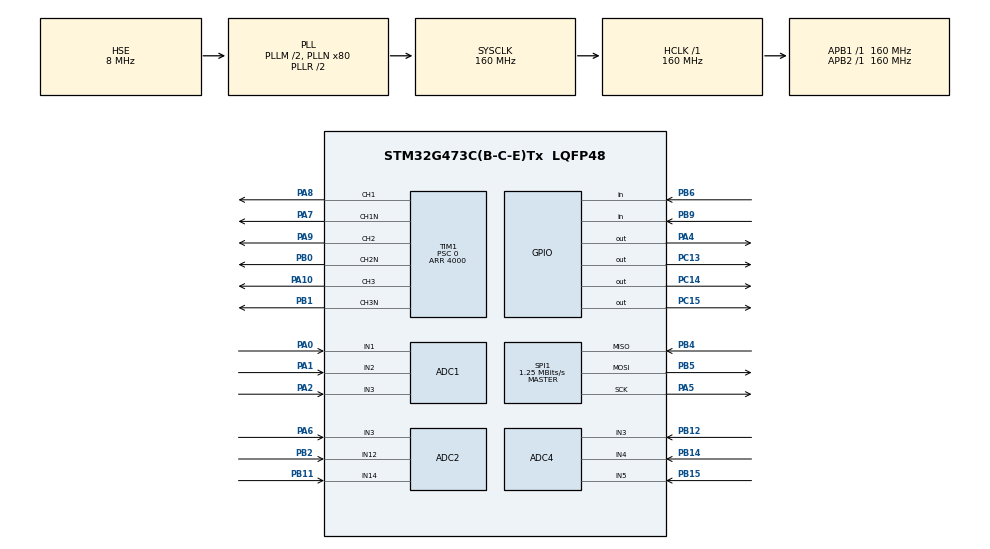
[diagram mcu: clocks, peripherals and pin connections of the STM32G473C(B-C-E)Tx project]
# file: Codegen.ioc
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ADC1.Channel-0\#ChannelRegularConversion=ADC_CHANNEL_1
ADC1.Channel-1\#ChannelRegularConversion=ADC_CHANNEL_2
ADC1.Channel-2\#ChannelRegularConversion=ADC_CHANNEL_3
ADC1.ClockPrescaler=ADC_CLOCK_ASYNC_DIV4
ADC1.ContinuousConvMode=DISABLE
ADC1.DMAContinuousRequests=ENABLE
ADC1.EOCSelection=ADC_EOC_SEQ_CONV
ADC1.EnableInjectedConversion=DISABLE
ADC1.ExternalTrigConv=ADC_EXTERNALTRIG_T1_TRGO2
ADC1.NbrOfConversion=3
ADC1.NbrOfConversionFlag=1
ADC1.OffsetNumber-0\#ChannelRegularConversion=ADC_OFFSET_NONE
ADC1.OffsetNumber-1\#ChannelRegularConversion=ADC_OFFSET_NONE
ADC1.OffsetNumber-2\#ChannelRegularConversion=ADC_OFFSET_NONE
ADC1.Rank-0\#ChannelRegularConversion=1
ADC1.Rank-1\#ChannelRegularConversion=2
ADC1.Rank-2\#ChannelRegularConversion=3
ADC1.SamplingTime-0\#ChannelRegularConversion=ADC_SAMPLETIME_2CYCLES_5
ADC1.SamplingTime-1\#ChannelRegularConversion=ADC_SAMPLETIME_2CYCLES_5
ADC1.SamplingTime-2\#ChannelRegularConversion=ADC_SAMPLETIME_2CYCLES_5
ADC1.master=1
ADC2.Channel-0\#ChannelRegularConversion=ADC_CHANNEL_3
ADC2.Channel-1\#ChannelRegularConversion=ADC_CHANNEL_12
ADC2.Channel-2\#ChannelRegularConversion=ADC_CHANNEL_14
ADC2.ClockPrescaler=ADC_CLOCK_ASYNC_DIV4
ADC2.ContinuousConvMode=DISABLE
ADC2.DMAContinuousRequests=ENABLE
ADC2.EOCSelection=ADC_EOC_SEQ_CONV
ADC2.ExternalTrigConv=ADC_EXTERNALTRIG_T1_TRGO2
ADC2.NbrOfConversion=3
ADC2.NbrOfConversionFlag=1
ADC2.OffsetNumber-0\#ChannelRegularConversion=ADC_OFFSET_NONE
ADC2.OffsetNumber-1\#ChannelRegularConversion=ADC_OFFSET_NONE
ADC2.OffsetNumber-2\#ChannelRegularConversion=ADC_OFFSET_NONE
ADC2.Rank-0\#ChannelRegularConversion=1
ADC2.Rank-1\#ChannelRegularConversion=2
ADC2.Rank-2\#ChannelRegularConversion=3
ADC2.SamplingTime-0\#ChannelRegularConversion=ADC_SAMPLETIME_2CYCLES_5
ADC2.SamplingTime-1\#ChannelRegularConversion=ADC_SAMPLETIME_2CYCLES_5
ADC2.SamplingTime-2\#ChannelRegularConversion=ADC_SAMPLETIME_2CYCLES_5
ADC4.Channel-0\#ChannelRegularConversion=ADC_CHANNEL_3
ADC4.Channel-1\#ChannelRegularConversion=ADC_CHANNEL_4
ADC4.Channel-2\#ChannelRegularConversion=ADC_CHANNEL_5
ADC4.ClockPrescaler=ADC_CLOCK_ASYNC_DIV4
ADC4.ContinuousConvMode=DISABLE
ADC4.DMAContinuousRequests=ENABLE
ADC4.EOCSelection=ADC_EOC_SEQ_CONV
ADC4.ExternalTrigConv=ADC_EXTERNALTRIG_T1_TRGO2
ADC4.NbrOfConversion=3
ADC4.NbrOfConversionFlag=1
ADC4.OffsetNumber-0\#ChannelRegularConversion=ADC_OFFSET_NONE
ADC4.OffsetNumber-1\#ChannelRegularConversion=ADC_OFFSET_NONE
ADC4.OffsetNumber-2\#ChannelRegularConversion=ADC_OFFSET_NONE
ADC4.Rank-0\#ChannelRegularConversion=1
ADC4.Rank-1\#ChannelRegularConversion=2
ADC4.Rank-2\#ChannelRegularConversion=3
ADC4.SamplingTime-0\#ChannelRegularConversion=ADC_SAMPLETIME_2CYCLES_5
ADC4.SamplingTime-1\#ChannelRegularConversion=ADC_SAMPLETIME_2CYCLES_5
ADC4.SamplingTime-2\#ChannelRegularConversion=ADC_SAMPLETIME_2CYCLES_5
Dma.ADC1.0.Direction=DMA_PERIPH_TO_MEMORY
Dma.ADC1.0.EventEnable=DISABLE
Dma.ADC1.0.Instance=DMA1_Channel1
Dma.ADC1.0.MemDataAlignment=DMA_MDATAALIGN_WORD
Dma.ADC1.0.MemInc=DMA_MINC_ENABLE
Dma.ADC1.0.Mode=DMA_CIRCULAR
Dma.ADC1.0.PeriphDataAlignment=DMA_PDATAALIGN_WORD
Dma.ADC1.0.PeriphInc=DMA_PINC_DISABLE
Dma.ADC1.0.Polarity=HAL_DMAMUX_REQ_GEN_RISING
Dma.ADC1.0.Priority=DMA_PRIORITY_LOW
Dma.ADC1.0.RequestNumber=1
Dma.ADC1.0.SignalID=NONE
Dma.ADC1.0.SyncEnable=DISABLE
Dma.ADC1.0.SyncPolarity=HAL_DMAMUX_SYNC_NO_EVENT
Dma.ADC1.0.SyncRequestNumber=1
Dma.ADC1.0.SyncSignalID=NONE
Dma.ADC2.2.Direction=DMA_PERIPH_TO_MEMORY
Dma.ADC2.2.EventEnable=DISABLE
Dma.ADC2.2.Instance=DMA1_Channel3
Dma.ADC2.2.MemDataAlignment=DMA_MDATAALIGN_WORD
Dma.ADC2.2.MemInc=DMA_MINC_ENABLE
Dma.ADC2.2.Mode=DMA_CIRCULAR
Dma.ADC2.2.PeriphDataAlignment=DMA_PDATAALIGN_WORD
Dma.ADC2.2.PeriphInc=DMA_PINC_DISABLE
Dma.ADC2.2.Polarity=HAL_DMAMUX_REQ_GEN_RISING
Dma.ADC2.2.Priority=DMA_PRIORITY_LOW
Dma.ADC2.2.RequestNumber=1
Dma.ADC2.2.SignalID=NONE
Dma.ADC2.2.SyncEnable=DISABLE
Dma.ADC2.2.SyncPolarity=HAL_DMAMUX_SYNC_NO_EVENT
Dma.ADC2.2.SyncRequestNumber=1
Dma.ADC2.2.SyncSignalID=NONE
Dma.ADC4.1.Direction=DMA_PERIPH_TO_MEMORY
Dma.ADC4.1.EventEnable=DISABLE
Dma.ADC4.1.Instance=DMA1_Channel2
Dma.ADC4.1.MemDataAlignment=DMA_MDATAALIGN_WORD
Dma.ADC4.1.MemInc=DMA_MINC_ENABLE
Dma.ADC4.1.Mode=DMA_CIRCULAR
Dma.ADC4.1.PeriphDataAlignment=DMA_PDATAALIGN_WORD
Dma.ADC4.1.PeriphInc=DMA_PINC_DISABLE
Dma.ADC4.1.Polarity=HAL_DMAMUX_REQ_GEN_RISING
Dma.ADC4.1.Priority=DMA_PRIORITY_LOW
Dma.ADC4.1.RequestNumber=1
Dma.ADC4.1.SignalID=NONE
Dma.ADC4.1.SyncEnable=DISABLE
Dma.ADC4.1.SyncPolarity=HAL_DMAMUX_SYNC_NO_EVENT
Dma.ADC4.1.SyncRequestNumber=1
Dma.ADC4.1.SyncSignalID=NONE
Dma.Request0=ADC1
Dma.Request1=ADC4
Dma.Request2=ADC2
Dma.Request3=SPI1_RX
Dma.Request4=SPI1_TX
Dma.SPI1_RX.3.Direction=DMA_PERIPH_TO_MEMORY
Dma.SPI1_RX.3.EventEnable=DISABLE
Dma.SPI1_RX.3.Instance=DMA1_Channel4
Dma.SPI1_RX.3.MemDataAlignment=DMA_MDATAALIGN_HALFWORD
Dma.SPI1_RX.3.MemInc=DMA_MINC_ENABLE
Dma.SPI1_RX.3.Mode=DMA_NORMAL
Dma.SPI1_RX.3.PeriphDataAlignment=DMA_PDATAALIGN_HALFWORD
Dma.SPI1_RX.3.PeriphInc=DMA_PINC_DISABLE
Dma.SPI1_RX.3.Polarity=HAL_DMAMUX_REQ_GEN_RISING
Dma.SPI1_RX.3.Priority=DMA_PRIORITY_LOW
Dma.SPI1_RX.3.RequestNumber=1
Dma.SPI1_RX.3.SignalID=NONE
Dma.SPI1_RX.3.SyncEnable=DISABLE
Dma.SPI1_RX.3.SyncPolarity=HAL_DMAMUX_SYNC_NO_EVENT
Dma.SPI1_RX.3.SyncRequestNumber=1
Dma.SPI1_RX.3.SyncSignalID=NONE
Dma.SPI1_TX.4.Direction=DMA_MEMORY_TO_PERIPH
Dma.SPI1_TX.4.EventEnable=DISABLE
Dma.SPI1_TX.4.Instance=DMA1_Channel5
Dma.SPI1_TX.4.MemDataAlignment=DMA_MDATAALIGN_HALFWORD
Dma.SPI1_TX.4.MemInc=DMA_MINC_ENABLE
Dma.SPI1_TX.4.Mode=DMA_NORMAL
Dma.SPI1_TX.4.PeriphDataAlignment=DMA_PDATAALIGN_HALFWORD
Dma.SPI1_TX.4.PeriphInc=DMA_PINC_DISABLE
Dma.SPI1_TX.4.Polarity=HAL_DMAMUX_REQ_GEN_RISING
Dma.SPI1_TX.4.Priority=DMA_PRIORITY_LOW
Dma.SPI1_TX.4.RequestNumber=1
Dma.SPI1_TX.4.SignalID=NONE
Dma.SPI1_TX.4.SyncEnable=DISABLE
Dma.SPI1_TX.4.SyncPolarity=HAL_DMAMUX_SYNC_NO_EVENT
Dma.SPI1_TX.4.SyncRequestNumber=1
Dma.SPI1_TX.4.SyncSignalID=NONE
FREERTOS.Tasks01=defaultTask,24,128,StartDefaultTask,Default,NULL,Dynamic,NULL,NULL;HLC,32,128,task_hlc,As external,NULL,Dynamic,NULL,NULL;BGT,24,128,task_bgt,As external,NULL,Dynamic,NULL,NULL
FREERTOS.configENABLE_FPU=1
Mcu.Family=STM32G4
Mcu.Name=STM32G473C(B-C-E)Tx
Mcu.Package=LQFP48
NVIC.DMA1_Channel1_IRQn=true\:0\:0\:false\:false\:true\:true\:false\:true
NVIC.DMA1_Channel2_IRQn=true\:0\:0\:false\:false\:true\:true\:false\:true
NVIC.DMA1_Channel3_IRQn=true\:0\:0\:false\:false\:true\:true\:false\:true
NVIC.DMA1_Channel4_IRQn=true\:0\:0\:false\:false\:true\:true\:false\:true
NVIC.DMA1_Channel5_IRQn=true\:0\:0\:false\:false\:true\:true\:false\:true
NVIC.PriorityGroup=NVIC_PRIORITYGROUP_4
NVIC.TIM1_UP_TIM16_IRQn=true\:0\:0\:false\:false\:true\:false\:true\:true
NVIC.TIM2_IRQn=true\:0\:0\:false\:false\:true\:false\:false\:true
NVIC.TimeBase=TIM2_IRQn
NVIC.TimeBaseIP=TIM2
PA0.Mode=IN1-Single-Ended
PA0.Signal=ADC1_IN1
PA1.Mode=IN2-Single-Ended
PA1.Signal=ADC1_IN2
PA10.Signal=S_TIM1_CH3
PA13.Mode=Trace_Asynchronous_SW
PA13.Signal=SYS_JTMS-SWDIO
PA14.Mode=Trace_Asynchronous_SW
PA14.Signal=SYS_JTCK-SWCLK
PA2.Mode=IN3-Single-Ended
PA2.Signal=ADC1_IN3
PA4.Signal=GPIO_Output
PA5.Mode=Full_Duplex_Master
PA5.Signal=SPI1_SCK
PA6.Mode=IN3-Single-Ended
PA6.Signal=ADC2_IN3
PA7.Mode=PWM Generation1 CH1 CH1N
PA7.Signal=TIM1_CH1N
PA8.Signal=S_TIM1_CH1
PA9.Signal=S_TIM1_CH2
PB0.Mode=PWM Generation2 CH2 CH2N
PB0.Signal=TIM1_CH2N
PB1.Mode=PWM Generation3 CH3 CH3N
PB1.Signal=TIM1_CH3N
PB11.Mode=IN14-Single-Ended
PB11.Signal=ADC2_IN14
PB12.Mode=IN3-Single-Ended
PB12.Signal=ADC4_IN3
PB14.Mode=IN4-Single-Ended
PB14.Signal=ADC4_IN4
PB15.Mode=IN5-Single-Ended
PB15.Signal=ADC4_IN5
PB2.Mode=IN12-Single-Ended
PB2.Signal=ADC2_IN12
PB3.Mode=Trace_Asynchronous_SW
PB3.Signal=SYS_JTDO-SWO
PB4.Mode=Full_Duplex_Master
PB4.Signal=SPI1_MISO
PB5.Mode=Full_Duplex_Master
PB5.Signal=SPI1_MOSI
PB6.GPIO_PuPd=GPIO_PULLUP
PB6.Signal=GPIO_Input
PB9.GPIO_PuPd=GPIO_PULLUP
PB9.Signal=GPIO_Input
PC13.Signal=GPIO_Output
PC14-OSC32_IN.Signal=GPIO_Output
PC15-OSC32_OUT.Signal=GPIO_Output
PF0-OSC_IN.Mode=HSE-External-Oscillator
PF0-OSC_IN.Signal=RCC_OSC_IN
PF1-OSC_OUT.Mode=HSE-External-Oscillator
PF1-OSC_OUT.Signal=RCC_OSC_OUT
ProjectManager.HeapSize=0x200
ProjectManager.StackSize=0x400
ProjectManager.TargetToolchain=Makefile
RCC.ADC12CLockSelection=RCC_ADC12CLKSOURCE_PLL
RCC.ADC12Freq_Value=32000000
RCC.ADC345CLockSelection=RCC_ADC345CLKSOURCE_PLL
RCC.ADC345Freq_Value=32000000
RCC.AHBFreq_Value=160000000
RCC.APB1Freq_Value=160000000
RCC.APB1TimFreq_Value=160000000
RCC.APB2Freq_Value=160000000
RCC.APB2TimFreq_Value=160000000
RCC.CortexFreq_Value=160000000
RCC.EXTERNAL_CLOCK_VALUE=12288000
RCC.HCLKFreq_Value=160000000
RCC.HSE_VALUE=8000000
RCC.HSI48_VALUE=48000000
RCC.HSI_VALUE=16000000
RCC.LSE_VALUE=32768
RCC.PLLM=RCC_PLLM_DIV2
RCC.PLLN=80
RCC.PLLP=RCC_PLLP_DIV10
RCC.PLLSourceVirtual=RCC_PLLSOURCE_HSE
RCC.SYSCLKFreq_VALUE=160000000
RCC.SYSCLKSource=RCC_SYSCLKSOURCE_PLLCLK
RCC.USBFreq_Value=160000000
RCC.VCOOutputFreq_Value=320000000
SH.S_TIM1_CH1.0=TIM1_CH1,PWM Generation1 CH1 CH1N
SH.S_TIM1_CH2.0=TIM1_CH2,PWM Generation2 CH2 CH2N
SH.S_TIM1_CH3.0=TIM1_CH3,PWM Generation3 CH3 CH3N
SPI1.BaudRatePrescaler=SPI_BAUDRATEPRESCALER_128
SPI1.CLKPhase=SPI_PHASE_2EDGE
SPI1.CRCCalculation=SPI_CRCCALCULATION_DISABLE
SPI1.CalculateBaudRate=1.25 MBits/s
SPI1.DataSize=SPI_DATASIZE_16BIT
SPI1.Direction=SPI_DIRECTION_2LINES
SPI1.Mode=SPI_MODE_MASTER
SPI1.TIMode=SPI_TIMODE_DISABLE
SPI1.VirtualType=VM_MASTER
TIM1.BreakState=TIM_BREAK_DISABLE
TIM1.Channel-PWM\ Generation1\ CH1\ CH1N=TIM_CHANNEL_1
TIM1.Channel-PWM\ Generation2\ CH2\ CH2N=TIM_CHANNEL_2
TIM1.Channel-PWM\ Generation3\ CH3\ CH3N=TIM_CHANNEL_3
TIM1.Channel-PWM\ Generation5\ No\ Output=TIM_CHANNEL_5
TIM1.CounterMode=TIM_COUNTERMODE_CENTERALIGNED1
TIM1.DeadTime=0
TIM1.Dithering=Disable
TIM1.OCIdleState_1=TIM_OCIDLESTATE_RESET
TIM1.OCIdleState_2=TIM_OCIDLESTATE_RESET
TIM1.OCIdleState_3=TIM_OCIDLESTATE_RESET
TIM1.OCMode_PWM-PWM\ Generation1\ CH1\ CH1N=TIM_OCMODE_PWM2
TIM1.OCMode_PWM-PWM\ Generation2\ CH2\ CH2N=TIM_OCMODE_PWM2
TIM1.OCMode_PWM-PWM\ Generation3\ CH3\ CH3N=TIM_OCMODE_PWM2
TIM1.OCPolarity_1=TIM_OCPOLARITY_HIGH
TIM1.OCPolarity_2=TIM_OCPOLARITY_HIGH
TIM1.OCPolarity_3=TIM_OCPOLARITY_HIGH
TIM1.PeriodNoDither=4000
TIM1.Prescaler=0
TIM1.PulseNoDither_1=0
TIM1.PulseNoDither_5=1
TIM1.TIM_MasterOutputTrigger=TIM_TRGO_RESET
TIM1.TIM_MasterOutputTrigger2=TIM_TRGO2_OC5REF
TIM3.Channel-Output\ Compare1\ No\ Output=TIM_CHANNEL_1
TIM3.Prescaler=159
VP_FREERTOS_VS_CMSIS_V2.Mode=CMSIS_V2
VP_SYS_VS_DBSignals.Mode=DisableDeadBatterySignals
VP_SYS_VS_tim2.Mode=TIM2
VP_TIM1_VS_no_output5.Mode=PWM Generation5 No Output
VP_TIM3_VS_no_output1.Mode=Output Compare1 No Output
board=custom

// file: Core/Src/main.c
/* USER CODE BEGIN Header */
/**
  ******************************************************************************
  *
  * MBLDC FIRMWARE
  * By Maakbaas
  *
  ******************************************************************************
  */
/* USER CODE END Header */
#include "main.h"
#include "cmsis_os.h"

/* USER CODE BEGIN Includes */
#include "mbldc.h"

/* USER CODE END Includes */

ADC_HandleTypeDef hadc1;
ADC_HandleTypeDef hadc2;
ADC_HandleTypeDef hadc4;
DMA_HandleTypeDef hdma_adc1;
DMA_HandleTypeDef hdma_adc2;
DMA_HandleTypeDef hdma_adc4;

SPI_HandleTypeDef hspi1;
DMA_HandleTypeDef hdma_spi1_rx;
DMA_HandleTypeDef hdma_spi1_tx;

TIM_HandleTypeDef htim1;
TIM_HandleTypeDef htim3;

/* Definitions for defaultTask */
osThreadId_t defaultTaskHandle;
const osThreadAttr_t defaultTask_attributes = {
  .name = "defaultTask",
  .priority = (osPriority_t) osPriorityNormal,
  .stack_size = 128 * 4
};
/* Definitions for HLC */
osThreadId_t HLCHandle;
const osThreadAttr_t HLC_attributes = {
  .name = "HLC",
  .priority = (osPriority_t) osPriorityAboveNormal,
  .stack_size = 128 * 4
};
/* Definitions for BGT */
osThreadId_t BGTHandle;
const osThreadAttr_t BGT_attributes = {
  .name = "BGT",
  .priority = (osPriority_t) osPriorityNormal,
  .stack_size = 128 * 4
};

void SystemClock_Config(void);
static void MX_GPIO_Init(void);
static void MX_DMA_Init(void);
static void MX_ADC1_Init(void);
static void MX_ADC4_Init(void);
static void MX_ADC2_Init(void);
static void MX_SPI1_Init(void);
static void MX_TIM1_Init(void);
static void MX_TIM3_Init(void);
void StartDefaultTask(void *argument);
extern void task_hlc(void *argument);
extern void task_bgt(void *argument);

int main(void)
{
  /* USER CODE BEGIN 1 */
  STM32_DisableBootPin();

  /* USER CODE END 1 */

  /* MCU Configuration--------------------------------------------------------*/

  /* Reset of all peripherals, Initializes the Flash interface and the Systick. */
  HAL_Init();

  /* Configure the system clock */
  SystemClock_Config();

  /* Initialize all configured peripherals */
  MX_GPIO_Init();
  MX_DMA_Init();
  MX_ADC1_Init();
  MX_ADC4_Init();
  MX_ADC2_Init();
  MX_SPI1_Init();
  MX_TIM1_Init();
  MX_TIM3_Init();

  /* Init scheduler */
  osKernelInitialize();

  /* Create the thread(s) */
  /* creation of defaultTask */
  defaultTaskHandle = osThreadNew(StartDefaultTask, NULL, &defaultTask_attributes);

  /* creation of HLC */
  HLCHandle = osThreadNew(task_hlc, NULL, &HLC_attributes);

  /* creation of BGT */
  BGTHandle = osThreadNew(task_bgt, NULL, &BGT_attributes);

  /* Start scheduler */
  osKernelStart();

  /* We should never get here as control is now taken by the scheduler */
  /* Infinite loop */
  while (1)
  {

  }
}

void SystemClock_Config(void)
{
  RCC_OscInitTypeDef RCC_OscInitStruct = {0};
  RCC_ClkInitTypeDef RCC_ClkInitStruct = {0};
  RCC_PeriphCLKInitTypeDef PeriphClkInit = {0};

  /** Configure the main internal regulator output voltage
  */
  HAL_PWREx_ControlVoltageScaling(PWR_REGULATOR_VOLTAGE_SCALE1_BOOST);
  /** Initializes the RCC Oscillators according to the specified parameters
  * in the RCC_OscInitTypeDef structure.
  */
  RCC_OscInitStruct.OscillatorType = RCC_OSCILLATORTYPE_HSE;
  RCC_OscInitStruct.HSEState = RCC_HSE_ON;
  RCC_OscInitStruct.PLL.PLLState = RCC_PLL_ON;
  RCC_OscInitStruct.PLL.PLLSource = RCC_PLLSOURCE_HSE;
  RCC_OscInitStruct.PLL.PLLM = RCC_PLLM_DIV2;
  RCC_OscInitStruct.PLL.PLLN = 80;
  RCC_OscInitStruct.PLL.PLLP = RCC_PLLP_DIV10;
  RCC_OscInitStruct.PLL.PLLQ = RCC_PLLQ_DIV2;
  RCC_OscInitStruct.PLL.PLLR = RCC_PLLR_DIV2;
  if (HAL_RCC_OscConfig(&RCC_OscInitStruct) != HAL_OK)
  {
    Error_Handler();
  }
  /** Initializes the CPU, AHB and APB buses clocks
  */
  RCC_ClkInitStruct.ClockType = RCC_CLOCKTYPE_HCLK|RCC_CLOCKTYPE_SYSCLK
                              |RCC_CLOCKTYPE_PCLK1|RCC_CLOCKTYPE_PCLK2;
  RCC_ClkInitStruct.SYSCLKSource = RCC_SYSCLKSOURCE_PLLCLK;
  RCC_ClkInitStruct.AHBCLKDivider = RCC_SYSCLK_DIV1;
  RCC_ClkInitStruct.APB1CLKDivider = RCC_HCLK_DIV1;
  RCC_ClkInitStruct.APB2CLKDivider = RCC_HCLK_DIV1;

  if (HAL_RCC_ClockConfig(&RCC_ClkInitStruct, FLASH_LATENCY_4) != HAL_OK)
  {
    Error_Handler();
  }
  /** Initializes the peripherals clocks
  */
  PeriphClkInit.PeriphClockSelection = RCC_PERIPHCLK_ADC12|RCC_PERIPHCLK_ADC345;
  PeriphClkInit.Adc12ClockSelection = RCC_ADC12CLKSOURCE_PLL;
  PeriphClkInit.Adc345ClockSelection = RCC_ADC345CLKSOURCE_PLL;
  if (HAL_RCCEx_PeriphCLKConfig(&PeriphClkInit) != HAL_OK)
  {
    Error_Handler();
  }
}

static void MX_ADC1_Init(void)
{

  ADC_MultiModeTypeDef multimode = {0};
  ADC_ChannelConfTypeDef sConfig = {0};

  /** Common config
  */
  hadc1.Instance = ADC1;
  hadc1.Init.ClockPrescaler = ADC_CLOCK_ASYNC_DIV4;
  hadc1.Init.Resolution = ADC_RESOLUTION_12B;
  hadc1.Init.DataAlign = ADC_DATAALIGN_RIGHT;
  hadc1.Init.GainCompensation = 0;
  hadc1.Init.ScanConvMode = ADC_SCAN_ENABLE;
  hadc1.Init.EOCSelection = ADC_EOC_SEQ_CONV;
  hadc1.Init.LowPowerAutoWait = DISABLE;
  hadc1.Init.ContinuousConvMode = DISABLE;
  hadc1.Init.NbrOfConversion = 3;
  hadc1.Init.DiscontinuousConvMode = DISABLE;
  hadc1.Init.ExternalTrigConv = ADC_EXTERNALTRIG_T1_TRGO2;
  hadc1.Init.ExternalTrigConvEdge = ADC_EXTERNALTRIGCONVEDGE_RISING;
  hadc1.Init.DMAContinuousRequests = ENABLE;
  hadc1.Init.Overrun = ADC_OVR_DATA_PRESERVED;
  hadc1.Init.OversamplingMode = DISABLE;
  if (HAL_ADC_Init(&hadc1) != HAL_OK)
  {
    Error_Handler();
  }
  /** Configure the ADC multi-mode
  */
  multimode.Mode = ADC_MODE_INDEPENDENT;
  if (HAL_ADCEx_MultiModeConfigChannel(&hadc1, &multimode) != HAL_OK)
  {
    Error_Handler();
  }
  /** Configure Regular Channel
  */
  sConfig.Channel = ADC_CHANNEL_1;
  sConfig.Rank = ADC_REGULAR_RANK_1;
  sConfig.SamplingTime = ADC_SAMPLETIME_2CYCLES_5;
  sConfig.SingleDiff = ADC_SINGLE_ENDED;
  sConfig.OffsetNumber = ADC_OFFSET_NONE;
  sConfig.Offset = 0;
  if (HAL_ADC_ConfigChannel(&hadc1, &sConfig) != HAL_OK)
  {
    Error_Handler();
  }
  /** Configure Regular Channel
  */
  sConfig.Channel = ADC_CHANNEL_2;
  sConfig.Rank = ADC_REGULAR_RANK_2;
  if (HAL_ADC_ConfigChannel(&hadc1, &sConfig) != HAL_OK)
  {
    Error_Handler();
  }
  /** Configure Regular Channel
  */
  sConfig.Channel = ADC_CHANNEL_3;
  sConfig.Rank = ADC_REGULAR_RANK_3;
  if (HAL_ADC_ConfigChannel(&hadc1, &sConfig) != HAL_OK)
  {
    Error_Handler();
  }

}

static void MX_ADC2_Init(void)
{

  ADC_ChannelConfTypeDef sConfig = {0};

  /** Common config
  */
  hadc2.Instance = ADC2;
  hadc2.Init.ClockPrescaler = ADC_CLOCK_ASYNC_DIV4;
  hadc2.Init.Resolution = ADC_RESOLUTION_12B;
  hadc2.Init.DataAlign = ADC_DATAALIGN_RIGHT;
  hadc2.Init.GainCompensation = 0;
  hadc2.Init.ScanConvMode = ADC_SCAN_ENABLE;
  hadc2.Init.EOCSelection = ADC_EOC_SEQ_CONV;
  hadc2.Init.LowPowerAutoWait = DISABLE;
  hadc2.Init.ContinuousConvMode = DISABLE;
  hadc2.Init.NbrOfConversion = 3;
  hadc2.Init.DiscontinuousConvMode = DISABLE;
  hadc2.Init.ExternalTrigConv = ADC_EXTERNALTRIG_T1_TRGO2;
  hadc2.Init.ExternalTrigConvEdge = ADC_EXTERNALTRIGCONVEDGE_RISING;
  hadc2.Init.DMAContinuousRequests = ENABLE;
  hadc2.Init.Overrun = ADC_OVR_DATA_PRESERVED;
  hadc2.Init.OversamplingMode = DISABLE;
  if (HAL_ADC_Init(&hadc2) != HAL_OK)
  {
    Error_Handler();
  }
  /** Configure Regular Channel
  */
  sConfig.Channel = ADC_CHANNEL_3;
  sConfig.Rank = ADC_REGULAR_RANK_1;
  sConfig.SamplingTime = ADC_SAMPLETIME_2CYCLES_5;
  sConfig.SingleDiff = ADC_SINGLE_ENDED;
  sConfig.OffsetNumber = ADC_OFFSET_NONE;
  sConfig.Offset = 0;
  if (HAL_ADC_ConfigChannel(&hadc2, &sConfig) != HAL_OK)
  {
    Error_Handler();
  }
  /** Configure Regular Channel
  */
  sConfig.Channel = ADC_CHANNEL_12;
  sConfig.Rank = ADC_REGULAR_RANK_2;
  if (HAL_ADC_ConfigChannel(&hadc2, &sConfig) != HAL_OK)
  {
    Error_Handler();
  }
  /** Configure Regular Channel
  */
  sConfig.Channel = ADC_CHANNEL_14;
  sConfig.Rank = ADC_REGULAR_RANK_3;
  if (HAL_ADC_ConfigChannel(&hadc2, &sConfig) != HAL_OK)
  {
    Error_Handler();
  }

}

static void MX_ADC4_Init(void)
{

  ADC_ChannelConfTypeDef sConfig = {0};

  /** Common config
  */
  hadc4.Instance = ADC4;
  hadc4.Init.ClockPrescaler = ADC_CLOCK_ASYNC_DIV4;
  hadc4.Init.Resolution = ADC_RESOLUTION_12B;
  hadc4.Init.DataAlign = ADC_DATAALIGN_RIGHT;
  hadc4.Init.GainCompensation = 0;
  hadc4.Init.ScanConvMode = ADC_SCAN_ENABLE;
  hadc4.Init.EOCSelection = ADC_EOC_SEQ_CONV;
  hadc4.Init.LowPowerAutoWait = DISABLE;
  hadc4.Init.ContinuousConvMode = DISABLE;
  hadc4.Init.NbrOfConversion = 3;
  hadc4.Init.DiscontinuousConvMode = DISABLE;
  hadc4.Init.ExternalTrigConv = ADC_EXTERNALTRIG_T1_TRGO2;
  hadc4.Init.ExternalTrigConvEdge = ADC_EXTERNALTRIGCONVEDGE_RISING;
  hadc4.Init.DMAContinuousRequests = ENABLE;
  hadc4.Init.Overrun = ADC_OVR_DATA_PRESERVED;
  hadc4.Init.OversamplingMode = DISABLE;
  if (HAL_ADC_Init(&hadc4) != HAL_OK)
  {
    Error_Handler();
  }
  /** Configure Regular Channel
  */
  sConfig.Channel = ADC_CHANNEL_3;
  sConfig.Rank = ADC_REGULAR_RANK_1;
  sConfig.SamplingTime = ADC_SAMPLETIME_2CYCLES_5;
  sConfig.SingleDiff = ADC_SINGLE_ENDED;
  sConfig.OffsetNumber = ADC_OFFSET_NONE;
  sConfig.Offset = 0;
  if (HAL_ADC_ConfigChannel(&hadc4, &sConfig) != HAL_OK)
  {
    Error_Handler();
  }
  /** Configure Regular Channel
  */
  sConfig.Channel = ADC_CHANNEL_4;
  sConfig.Rank = ADC_REGULAR_RANK_2;
  if (HAL_ADC_ConfigChannel(&hadc4, &sConfig) != HAL_OK)
  {
    Error_Handler();
  }
  /** Configure Regular Channel
  */
  sConfig.Channel = ADC_CHANNEL_5;
  sConfig.Rank = ADC_REGULAR_RANK_3;
  if (HAL_ADC_ConfigChannel(&hadc4, &sConfig) != HAL_OK)
  {
    Error_Handler();
  }

}

static void MX_SPI1_Init(void)
{

  /* SPI1 parameter configuration*/
  hspi1.Instance = SPI1;
  hspi1.Init.Mode = SPI_MODE_MASTER;
  hspi1.Init.Direction = SPI_DIRECTION_2LINES;
  hspi1.Init.DataSize = SPI_DATASIZE_16BIT;
  hspi1.Init.CLKPolarity = SPI_POLARITY_LOW;
  hspi1.Init.CLKPhase = SPI_PHASE_2EDGE;
  hspi1.Init.NSS = SPI_NSS_SOFT;
  hspi1.Init.BaudRatePrescaler = SPI_BAUDRATEPRESCALER_128;
  hspi1.Init.FirstBit = SPI_FIRSTBIT_MSB;
  hspi1.Init.TIMode = SPI_TIMODE_DISABLE;
  hspi1.Init.CRCCalculation = SPI_CRCCALCULATION_DISABLE;
  hspi1.Init.CRCPolynomial = 7;
  hspi1.Init.CRCLength = SPI_CRC_LENGTH_DATASIZE;
  hspi1.Init.NSSPMode = SPI_NSS_PULSE_DISABLE;
  if (HAL_SPI_Init(&hspi1) != HAL_OK)
  {
    Error_Handler();
  }

}

static void MX_TIM1_Init(void)
{

  TIM_MasterConfigTypeDef sMasterConfig = {0};
  TIM_OC_InitTypeDef sConfigOC = {0};
  TIM_BreakDeadTimeConfigTypeDef sBreakDeadTimeConfig = {0};

  htim1.Instance = TIM1;
  htim1.Init.Prescaler = 0;
  htim1.Init.CounterMode = TIM_COUNTERMODE_CENTERALIGNED1;
  htim1.Init.Period = 4000;
  htim1.Init.ClockDivision = TIM_CLOCKDIVISION_DIV1;
  htim1.Init.RepetitionCounter = 0;
  htim1.Init.AutoReloadPreload = TIM_AUTORELOAD_PRELOAD_DISABLE;
  if (HAL_TIM_PWM_Init(&htim1) != HAL_OK)
  {
    Error_Handler();
  }
  sMasterConfig.MasterOutputTrigger = TIM_TRGO_RESET;
  sMasterConfig.MasterOutputTrigger2 = TIM_TRGO2_OC5REF;
  sMasterConfig.MasterSlaveMode = TIM_MASTERSLAVEMODE_DISABLE;
  if (HAL_TIMEx_MasterConfigSynchronization(&htim1, &sMasterConfig) != HAL_OK)
  {
    Error_Handler();
  }
  sConfigOC.OCMode = TIM_OCMODE_PWM2;
  sConfigOC.Pulse = 0;
  sConfigOC.OCPolarity = TIM_OCPOLARITY_HIGH;
  sConfigOC.OCNPolarity = TIM_OCNPOLARITY_HIGH;
  sConfigOC.OCFastMode = TIM_OCFAST_DISABLE;
  sConfigOC.OCIdleState = TIM_OCIDLESTATE_RESET;
  sConfigOC.OCNIdleState = TIM_OCNIDLESTATE_RESET;
  if (HAL_TIM_PWM_ConfigChannel(&htim1, &sConfigOC, TIM_CHANNEL_1) != HAL_OK)
  {
    Error_Handler();
  }
  sConfigOC.Pulse = 0;
  if (HAL_TIM_PWM_ConfigChannel(&htim1, &sConfigOC, TIM_CHANNEL_2) != HAL_OK)
  {
    Error_Handler();
  }
  sConfigOC.Pulse = 0;
  if (HAL_TIM_PWM_ConfigChannel(&htim1, &sConfigOC, TIM_CHANNEL_3) != HAL_OK)
  {
    Error_Handler();
  }
  sConfigOC.OCMode = TIM_OCMODE_PWM1;
  sConfigOC.Pulse = 1;
  if (HAL_TIM_PWM_ConfigChannel(&htim1, &sConfigOC, TIM_CHANNEL_5) != HAL_OK)
  {
    Error_Handler();
  }
  sBreakDeadTimeConfig.OffStateRunMode = TIM_OSSR_DISABLE;
  sBreakDeadTimeConfig.OffStateIDLEMode = TIM_OSSI_DISABLE;
  sBreakDeadTimeConfig.LockLevel = TIM_LOCKLEVEL_OFF;
  sBreakDeadTimeConfig.DeadTime = 0;
  sBreakDeadTimeConfig.BreakState = TIM_BREAK_DISABLE;
  sBreakDeadTimeConfig.BreakPolarity = TIM_BREAKPOLARITY_HIGH;
  sBreakDeadTimeConfig.BreakFilter = 0;
  sBreakDeadTimeConfig.BreakAFMode = TIM_BREAK_AFMODE_INPUT;
  sBreakDeadTimeConfig.Break2State = TIM_BREAK2_DISABLE;
  sBreakDeadTimeConfig.Break2Polarity = TIM_BREAK2POLARITY_HIGH;
  sBreakDeadTimeConfig.Break2Filter = 0;
  sBreakDeadTimeConfig.Break2AFMode = TIM_BREAK_AFMODE_INPUT;
  sBreakDeadTimeConfig.AutomaticOutput = TIM_AUTOMATICOUTPUT_DISABLE;
  if (HAL_TIMEx_ConfigBreakDeadTime(&htim1, &sBreakDeadTimeConfig) != HAL_OK)
  {
    Error_Handler();
  }
  HAL_TIM_MspPostInit(&htim1);

}

static void MX_TIM3_Init(void)
{

  TIM_MasterConfigTypeDef sMasterConfig = {0};
  TIM_OC_InitTypeDef sConfigOC = {0};

  htim3.Instance = TIM3;
  htim3.Init.Prescaler = 159;
  htim3.Init.CounterMode = TIM_COUNTERMODE_UP;
  htim3.Init.Period = 65535;
  htim3.Init.ClockDivision = TIM_CLOCKDIVISION_DIV1;
  htim3.Init.AutoReloadPreload = TIM_AUTORELOAD_PRELOAD_DISABLE;
  if (HAL_TIM_OC_Init(&htim3) != HAL_OK)
  {
    Error_Handler();
  }
  sMasterConfig.MasterOutputTrigger = TIM_TRGO_RESET;
  sMasterConfig.MasterSlaveMode = TIM_MASTERSLAVEMODE_DISABLE;
  if (HAL_TIMEx_MasterConfigSynchronization(&htim3, &sMasterConfig) != HAL_OK)
  {
    Error_Handler();
  }
  sConfigOC.OCMode = TIM_OCMODE_TIMING;
  sConfigOC.Pulse = 0;
  sConfigOC.OCPolarity = TIM_OCPOLARITY_HIGH;
  sConfigOC.OCFastMode = TIM_OCFAST_DISABLE;
  if (HAL_TIM_OC_ConfigChannel(&htim3, &sConfigOC, TIM_CHANNEL_1) != HAL_OK)
  {
    Error_Handler();
  }

}

static void MX_DMA_Init(void)
{

  /* DMA controller clock enable */
  __HAL_RCC_DMAMUX1_CLK_ENABLE();
  __HAL_RCC_DMA1_CLK_ENABLE();

  /* DMA interrupt init */
  /* DMA1_Channel1_IRQn interrupt configuration */
  HAL_NVIC_SetPriority(DMA1_Channel1_IRQn, 0, 0);
  HAL_NVIC_EnableIRQ(DMA1_Channel1_IRQn);
  /* DMA1_Channel2_IRQn interrupt configuration */
  HAL_NVIC_SetPriority(DMA1_Channel2_IRQn, 0, 0);
  HAL_NVIC_EnableIRQ(DMA1_Channel2_IRQn);
  /* DMA1_Channel3_IRQn interrupt configuration */
  HAL_NVIC_SetPriority(DMA1_Channel3_IRQn, 0, 0);
  HAL_NVIC_EnableIRQ(DMA1_Channel3_IRQn);
  /* DMA1_Channel4_IRQn interrupt configuration */
  HAL_NVIC_SetPriority(DMA1_Channel4_IRQn, 0, 0);
  HAL_NVIC_EnableIRQ(DMA1_Channel4_IRQn);
  /* DMA1_Channel5_IRQn interrupt configuration */
  HAL_NVIC_SetPriority(DMA1_Channel5_IRQn, 0, 0);
  HAL_NVIC_EnableIRQ(DMA1_Channel5_IRQn);

}

static void MX_GPIO_Init(void)
{
  GPIO_InitTypeDef GPIO_InitStruct = {0};

  /* GPIO Ports Clock Enable */
  __HAL_RCC_GPIOC_CLK_ENABLE();
  __HAL_RCC_GPIOF_CLK_ENABLE();
  __HAL_RCC_GPIOA_CLK_ENABLE();
  __HAL_RCC_GPIOB_CLK_ENABLE();

  /*Configure GPIO pin Output Level */
  HAL_GPIO_WritePin(GPIOC, GPIO_PIN_13|GPIO_PIN_14|GPIO_PIN_15, GPIO_PIN_RESET);

  /*Configure GPIO pin Output Level */
  HAL_GPIO_WritePin(GPIOA, GPIO_PIN_4, GPIO_PIN_RESET);

  /*Configure GPIO pins : PC13 PC14 PC15 */
  GPIO_InitStruct.Pin = GPIO_PIN_13|GPIO_PIN_14|GPIO_PIN_15;
  GPIO_InitStruct.Mode = GPIO_MODE_OUTPUT_PP;
  GPIO_InitStruct.Pull = GPIO_NOPULL;
  GPIO_InitStruct.Speed = GPIO_SPEED_FREQ_LOW;
  HAL_GPIO_Init(GPIOC, &GPIO_InitStruct);

  /*Configure GPIO pin : PA4 */
  GPIO_InitStruct.Pin = GPIO_PIN_4;
  GPIO_InitStruct.Mode = GPIO_MODE_OUTPUT_PP;
  GPIO_InitStruct.Pull = GPIO_NOPULL;
  GPIO_InitStruct.Speed = GPIO_SPEED_FREQ_LOW;
  HAL_GPIO_Init(GPIOA, &GPIO_InitStruct);

  /*Configure GPIO pins : PB6 PB9 */
  GPIO_InitStruct.Pin = GPIO_PIN_6|GPIO_PIN_9;
  GPIO_InitStruct.Mode = GPIO_MODE_INPUT;
  GPIO_InitStruct.Pull = GPIO_PULLUP;
  HAL_GPIO_Init(GPIOB, &GPIO_InitStruct);

}

void StartDefaultTask(void *argument)
{
  for(;;)
  {
  }
}

void HAL_TIM_PeriodElapsedCallback(TIM_HandleTypeDef *htim)
{
  /* USER CODE BEGIN Callback 0 */
  if (htim->Instance == TIM1)
  {
        if ((TIM1->CR1 & 0b10000)==0) //is counting up
        {
            TIM1->EGR |= TIM_EGR_COMG; //do commutation
        }
  }

  /* USER CODE END Callback 0 */
  if (htim->Instance == TIM2) {
    HAL_IncTick();
  }
}

void Error_Handler(void)
{
}

/************************ (C) COPYRIGHT STMicroelectronics *****END OF FILE****/
